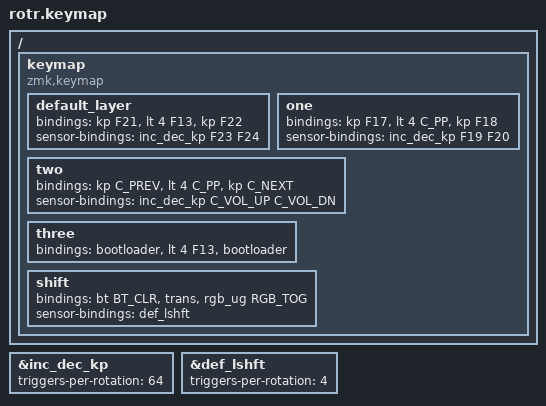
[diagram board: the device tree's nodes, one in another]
#include <behaviors.dtsi>
#include <dt-bindings/zmk/keys.h>
#include <dt-bindings/zmk/rgb.h>
#include <dt-bindings/zmk/bt.h>

&inc_dec_kp {
	triggers-per-rotation = <64>;
};
&def_lshft {
	triggers-per-rotation = <4>;
};

/ {
	keymap {
		compatible = "zmk,keymap";

		default_layer {
			//PREV | PLAY/PAUSE | NEXT
			bindings = <&kp F21 &lt 4 F13 &kp F22>;
			sensor-bindings = <&inc_dec_kp F23 F24>;
		};
		one {
			//PREV | PLAY/PAUSE | NEXT
			bindings = <&kp F17 &lt 4 C_PP &kp F18>;
			sensor-bindings = <&inc_dec_kp F19 F20>;
		};
		two {
			//PREV | PLAY/PAUSE | NEXT
			bindings = <&kp C_PREV &lt 4 C_PP &kp C_NEXT>;
			sensor-bindings = <&inc_dec_kp C_VOL_UP C_VOL_DN>;
		};
		three {
			//PREV | PLAY/PAUSE | NEXT
			bindings = <&bootloader &lt 4 F13 &bootloader>;
		};
		shift {
			//PREV | PLAY/PAUSE | NEXT
			bindings = <&bt BT_CLR &trans &rgb_ug RGB_TOG>;
			sensor-bindings = <&def_lshft>;
		};
	};
};
